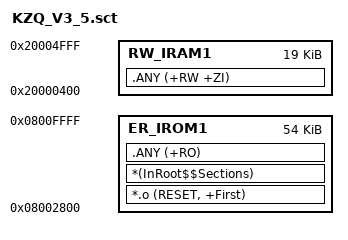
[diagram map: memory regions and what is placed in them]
; *************************************************************
; *** Scatter-Loading Description File generated by uVision ***
; *************************************************************

LR_IROM1 0x08002800 0x0000D800  {    ; load region size_region
  ER_IROM1 0x08002800 0x0000D800  {  ; load address = execution address
   *.o (RESET, +First)
   *(InRoot$$Sections)
   .ANY (+RO)
  }
  RW_IRAM1 0x20000400 0x00004C00  {  ; RW data
   .ANY (+RW +ZI)
  }
}

